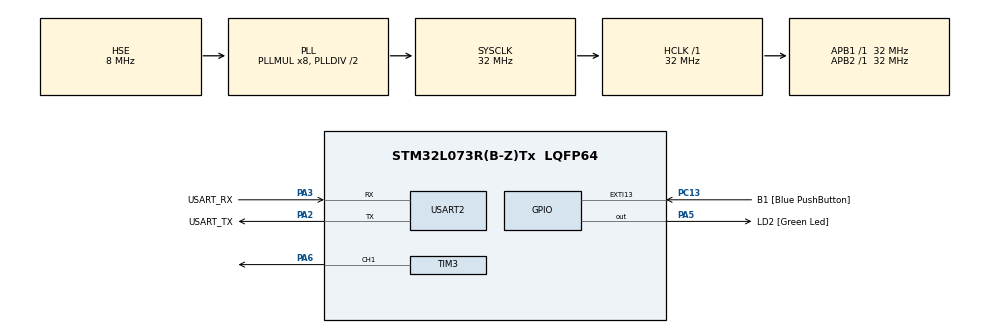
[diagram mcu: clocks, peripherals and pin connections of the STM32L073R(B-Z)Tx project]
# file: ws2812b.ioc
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Dma.Request0=TIM3_CH1
Dma.TIM3_CH1.0.Direction=DMA_MEMORY_TO_PERIPH
Dma.TIM3_CH1.0.Instance=DMA1_Channel5
Dma.TIM3_CH1.0.MemDataAlignment=DMA_MDATAALIGN_HALFWORD
Dma.TIM3_CH1.0.MemInc=DMA_MINC_ENABLE
Dma.TIM3_CH1.0.Mode=DMA_NORMAL
Dma.TIM3_CH1.0.PeriphDataAlignment=DMA_PDATAALIGN_HALFWORD
Dma.TIM3_CH1.0.PeriphInc=DMA_PINC_DISABLE
Dma.TIM3_CH1.0.Priority=DMA_PRIORITY_LOW
Mcu.Family=STM32L0
Mcu.Name=STM32L073R(B-Z)Tx
Mcu.Package=LQFP64
NVIC.DMA1_Channel4_5_6_7_IRQn=true\:0\:0\:false\:false\:true\:false\:true\:true
PA13.GPIO_Label=TMS
PA13.Mode=Serial_Wire
PA13.Signal=SYS_SWDIO
PA14.GPIO_Label=TCK
PA14.Mode=Serial_Wire
PA14.Signal=SYS_SWCLK
PA2.GPIO_Label=USART_TX
PA2.Mode=Asynchronous
PA2.Signal=USART2_TX
PA3.GPIO_Label=USART_RX
PA3.Mode=Asynchronous
PA3.Signal=USART2_RX
PA5.GPIO_Label=LD2 [Green Led]
PA5.Signal=GPIO_Output
PA6.Signal=S_TIM3_CH1
PC13.GPIO_Label=B1 [Blue PushButton]
PC13.GPIO_ModeDefaultEXTI=GPIO_MODE_IT_FALLING
PC13.Signal=GPXTI13
PC14-OSC32_IN.Mode=LSE-External-Oscillator
PC14-OSC32_IN.Signal=RCC_OSC32_IN
PC15-OSC32_OUT.Mode=LSE-External-Oscillator
PC15-OSC32_OUT.Signal=RCC_OSC32_OUT
PH0-OSC_IN.GPIO_Label=MCO
PH0-OSC_IN.Mode=HSE-External-Clock-Source
PH0-OSC_IN.Signal=RCC_OSC_IN
ProjectManager.HeapSize=0x200
ProjectManager.StackSize=0x400
ProjectManager.TargetToolchain=STM32CubeIDE
RCC.AHBFreq_Value=32000000
RCC.APB1Freq_Value=32000000
RCC.APB1TimFreq_Value=32000000
RCC.APB2Freq_Value=32000000
RCC.APB2TimFreq_Value=32000000
RCC.HCLKFreq_Value=32000000
RCC.HSE_VALUE=8000000
RCC.HSI16_VALUE=16000000
RCC.HSI48_VALUE=48000000
RCC.HSI_VALUE=16000000
RCC.MSI_VALUE=2097000
RCC.PLLMUL=RCC_PLLMUL_8
RCC.PLLSourceVirtual=RCC_PLLSOURCE_HSE
RCC.SYSCLKFreq_VALUE=32000000
RCC.SYSCLKSource=RCC_SYSCLKSOURCE_PLLCLK
RCC.VCOOutputFreq_Value=64000000
SH.S_TIM3_CH1.0=TIM3_CH1,PWM Generation1 CH1
TIM3.Channel-PWM\ Generation1\ CH1=TIM_CHANNEL_1
TIM3.Period=40-1
USART2.VirtualMode-Asynchronous=VM_ASYNC
VP_TIM3_VS_ClockSourceINT.Mode=Internal
board=NUCLEO-L073RZ

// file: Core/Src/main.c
/* USER CODE BEGIN Header */
/**
 ******************************************************************************
 * @file           : main.c
 * @brief          : Main program body
 ******************************************************************************
 * @attention
 *
 * Copyright (c) 2025 STMicroelectronics.
 * All rights reserved.
 *
 * This software is licensed under terms that can be found in the LICENSE file
 * in the root directory of this software component.
 * If no LICENSE file comes with this software, it is provided AS-IS.
 *
 ******************************************************************************
 */
/* USER CODE END Header */
#include "main.h"

/* USER CODE BEGIN Includes */
#include "ws2812b.h"
/* USER CODE END Includes */

TIM_HandleTypeDef htim3;
DMA_HandleTypeDef hdma_tim3_ch1;

UART_HandleTypeDef huart2;

void SystemClock_Config(void);
static void MX_GPIO_Init(void);
static void MX_DMA_Init(void);
static void MX_USART2_UART_Init(void);
static void MX_TIM3_Init(void);

/* USER CODE BEGIN 0 */
// max 1.25 us  for 40 value
uint8_t colors[][3] = { rgb(183, 39, 39), rgb(183, 181, 39), rgb(92, 183, 39),\
		rgb(39, 171, 183), rgb(39, 82, 183), rgb(164, 39, 183), rgb(183, 39,\
				128), rgb(183, 39, 61), rgb(249, 240, 242), rgb(6, 2, 112), rgb(\
				255, 222, 89), };

/* USER CODE END 0 */

int main(void)
{

  /* MCU Configuration--------------------------------------------------------*/

  /* Reset of all peripherals, Initializes the Flash interface and the Systick. */
  HAL_Init();

  /* Configure the system clock */
  SystemClock_Config();

  /* Initialize all configured peripherals */
  MX_GPIO_Init();
  MX_DMA_Init();
  MX_USART2_UART_Init();
  MX_TIM3_Init();
  /* USER CODE BEGIN 2 */
  HAL_TIM_Base_Start(&htim3);
  set_red_color();

  /* USER CODE END 2 */

  /* Infinite loop */
	while (1) {

    /* USER CODE BEGIN 3 */
//		for(int i =0; i<sizeof(colors)/sizeof(colors[0]);i++)
//		{
//			//uint8_t color_rgb[] = {colors[i][0], colors[i][1], colors[i][2]};
//
//			set_pixel_color(0, colors[i][0], colors[i][1], colors[i][2]);
//			set_pixel_color(1, colors[i][0], colors[i][1], colors[i][2]);
//			update_leds();
//			HAL_Delay(1000);
//			reset_colors();
//			HAL_Delay(1000);
//		}
		 set_red_color();
		 HAL_Delay(1000);
		 set_green_color();
		 HAL_Delay(1000);
		 set_blue_color();
		 HAL_Delay(1000);

	}
  /* USER CODE END 3 */
}

void SystemClock_Config(void)
{
  RCC_OscInitTypeDef RCC_OscInitStruct = {0};
  RCC_ClkInitTypeDef RCC_ClkInitStruct = {0};
  RCC_PeriphCLKInitTypeDef PeriphClkInit = {0};

  /** Configure the main internal regulator output voltage
  */
  __HAL_PWR_VOLTAGESCALING_CONFIG(PWR_REGULATOR_VOLTAGE_SCALE1);

  /** Initializes the RCC Oscillators according to the specified parameters
  * in the RCC_OscInitTypeDef structure.
  */
  RCC_OscInitStruct.OscillatorType = RCC_OSCILLATORTYPE_HSE;
  RCC_OscInitStruct.HSEState = RCC_HSE_BYPASS;
  RCC_OscInitStruct.PLL.PLLState = RCC_PLL_ON;
  RCC_OscInitStruct.PLL.PLLSource = RCC_PLLSOURCE_HSE;
  RCC_OscInitStruct.PLL.PLLMUL = RCC_PLLMUL_8;
  RCC_OscInitStruct.PLL.PLLDIV = RCC_PLLDIV_2;
  if (HAL_RCC_OscConfig(&RCC_OscInitStruct) != HAL_OK)
  {
    Error_Handler();
  }

  /** Initializes the CPU, AHB and APB buses clocks
  */
  RCC_ClkInitStruct.ClockType = RCC_CLOCKTYPE_HCLK|RCC_CLOCKTYPE_SYSCLK
                              |RCC_CLOCKTYPE_PCLK1|RCC_CLOCKTYPE_PCLK2;
  RCC_ClkInitStruct.SYSCLKSource = RCC_SYSCLKSOURCE_PLLCLK;
  RCC_ClkInitStruct.AHBCLKDivider = RCC_SYSCLK_DIV1;
  RCC_ClkInitStruct.APB1CLKDivider = RCC_HCLK_DIV1;
  RCC_ClkInitStruct.APB2CLKDivider = RCC_HCLK_DIV1;

  if (HAL_RCC_ClockConfig(&RCC_ClkInitStruct, FLASH_LATENCY_1) != HAL_OK)
  {
    Error_Handler();
  }
  PeriphClkInit.PeriphClockSelection = RCC_PERIPHCLK_USART2;
  PeriphClkInit.Usart2ClockSelection = RCC_USART2CLKSOURCE_PCLK1;
  if (HAL_RCCEx_PeriphCLKConfig(&PeriphClkInit) != HAL_OK)
  {
    Error_Handler();
  }
}

static void MX_TIM3_Init(void)
{

  TIM_ClockConfigTypeDef sClockSourceConfig = {0};
  TIM_MasterConfigTypeDef sMasterConfig = {0};
  TIM_OC_InitTypeDef sConfigOC = {0};

  htim3.Instance = TIM3;
  htim3.Init.Prescaler = 0;
  htim3.Init.CounterMode = TIM_COUNTERMODE_UP;
  htim3.Init.Period = 40-1;
  htim3.Init.ClockDivision = TIM_CLOCKDIVISION_DIV1;
  htim3.Init.AutoReloadPreload = TIM_AUTORELOAD_PRELOAD_DISABLE;
  if (HAL_TIM_Base_Init(&htim3) != HAL_OK)
  {
    Error_Handler();
  }
  sClockSourceConfig.ClockSource = TIM_CLOCKSOURCE_INTERNAL;
  if (HAL_TIM_ConfigClockSource(&htim3, &sClockSourceConfig) != HAL_OK)
  {
    Error_Handler();
  }
  if (HAL_TIM_PWM_Init(&htim3) != HAL_OK)
  {
    Error_Handler();
  }
  sMasterConfig.MasterOutputTrigger = TIM_TRGO_RESET;
  sMasterConfig.MasterSlaveMode = TIM_MASTERSLAVEMODE_DISABLE;
  if (HAL_TIMEx_MasterConfigSynchronization(&htim3, &sMasterConfig) != HAL_OK)
  {
    Error_Handler();
  }
  sConfigOC.OCMode = TIM_OCMODE_PWM1;
  sConfigOC.Pulse = 0;
  sConfigOC.OCPolarity = TIM_OCPOLARITY_HIGH;
  sConfigOC.OCFastMode = TIM_OCFAST_DISABLE;
  if (HAL_TIM_PWM_ConfigChannel(&htim3, &sConfigOC, TIM_CHANNEL_1) != HAL_OK)
  {
    Error_Handler();
  }
  if (HAL_TIMEx_RemapConfig(&htim3, TIM3_TI1_GPIO) != HAL_OK)
  {
    Error_Handler();
  }
  HAL_TIM_MspPostInit(&htim3);

}

static void MX_USART2_UART_Init(void)
{

  huart2.Instance = USART2;
  huart2.Init.BaudRate = 115200;
  huart2.Init.WordLength = UART_WORDLENGTH_8B;
  huart2.Init.StopBits = UART_STOPBITS_1;
  huart2.Init.Parity = UART_PARITY_NONE;
  huart2.Init.Mode = UART_MODE_TX_RX;
  huart2.Init.HwFlowCtl = UART_HWCONTROL_NONE;
  huart2.Init.OverSampling = UART_OVERSAMPLING_16;
  huart2.Init.OneBitSampling = UART_ONE_BIT_SAMPLE_DISABLE;
  huart2.AdvancedInit.AdvFeatureInit = UART_ADVFEATURE_NO_INIT;
  if (HAL_UART_Init(&huart2) != HAL_OK)
  {
    Error_Handler();
  }

}

static void MX_DMA_Init(void)
{

  /* DMA controller clock enable */
  __HAL_RCC_DMA1_CLK_ENABLE();

  /* DMA interrupt init */
  /* DMA1_Channel4_5_6_7_IRQn interrupt configuration */
  HAL_NVIC_SetPriority(DMA1_Channel4_5_6_7_IRQn, 0, 0);
  HAL_NVIC_EnableIRQ(DMA1_Channel4_5_6_7_IRQn);

}

static void MX_GPIO_Init(void)
{
  GPIO_InitTypeDef GPIO_InitStruct = {0};

  /* GPIO Ports Clock Enable */
  __HAL_RCC_GPIOC_CLK_ENABLE();
  __HAL_RCC_GPIOH_CLK_ENABLE();
  __HAL_RCC_GPIOA_CLK_ENABLE();

  /*Configure GPIO pin Output Level */
  HAL_GPIO_WritePin(LD2_GPIO_Port, LD2_Pin, GPIO_PIN_RESET);

  /*Configure GPIO pin : B1_Pin */
  GPIO_InitStruct.Pin = B1_Pin;
  GPIO_InitStruct.Mode = GPIO_MODE_IT_FALLING;
  GPIO_InitStruct.Pull = GPIO_NOPULL;
  HAL_GPIO_Init(B1_GPIO_Port, &GPIO_InitStruct);

  /*Configure GPIO pin : LD2_Pin */
  GPIO_InitStruct.Pin = LD2_Pin;
  GPIO_InitStruct.Mode = GPIO_MODE_OUTPUT_PP;
  GPIO_InitStruct.Pull = GPIO_NOPULL;
  GPIO_InitStruct.Speed = GPIO_SPEED_FREQ_LOW;
  HAL_GPIO_Init(LD2_GPIO_Port, &GPIO_InitStruct);

}

void Error_Handler(void)
{
	__disable_irq();
	while (1) {
	}
}
